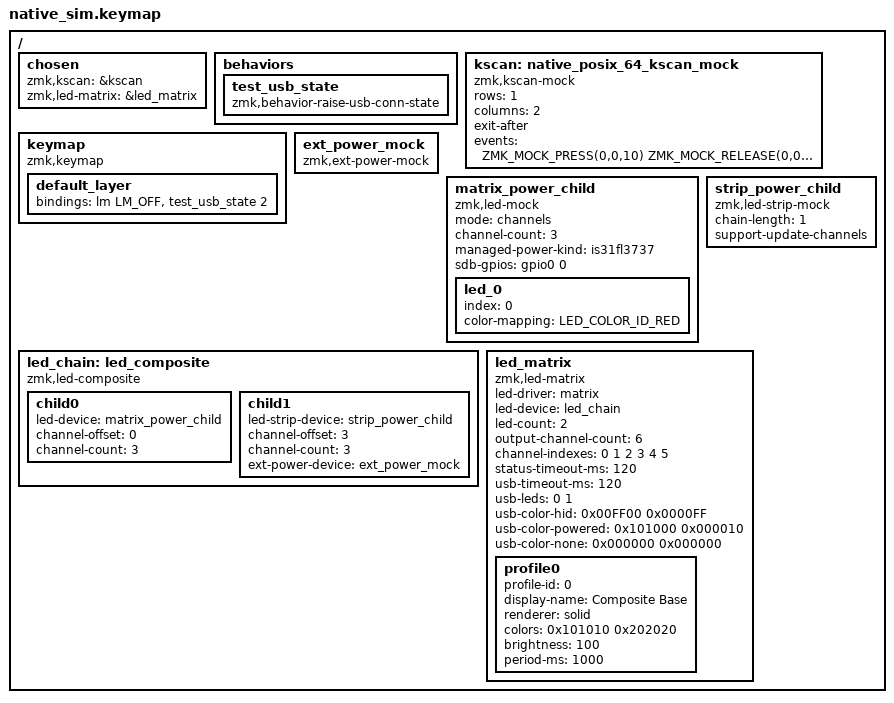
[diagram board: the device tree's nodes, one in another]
#include <dt-bindings/zmk/keys.h>
#include <dt-bindings/zmk/kscan_mock.h>
#include <dt-bindings/zmk/led_matrix.h>
#include <dt-bindings/led/led.h>
#include <behaviors.dtsi>

/ {
    chosen {
        zmk,kscan = &kscan;
        zmk,led-matrix = &led_matrix;
    };

    behaviors {
        test_usb_state: test_usb_state {
            compatible = "zmk,behavior-raise-usb-conn-state";
            #binding-cells = <1>;
        };
    };

    kscan: native_posix_64_kscan_mock {
        compatible = "zmk,kscan-mock";
        rows = <1>;
        columns = <2>;
        exit-after;
        events = <
            ZMK_MOCK_PRESS(0,0,10)
            ZMK_MOCK_RELEASE(0,0,10)
            ZMK_MOCK_PRESS(0,1,20)
            ZMK_MOCK_RELEASE(0,1,200)
        >;
    };

    keymap {
        compatible = "zmk,keymap";

        default_layer {
            bindings = <
                &lm LM_OFF
                &test_usb_state 2
            >;
        };
    };

    ext_power_mock: ext_power_mock {
        compatible = "zmk,ext-power-mock";
    };

    matrix_power_child: matrix_power_child {
        compatible = "zmk,led-mock";
        mode = "channels";
        channel-count = <3>;
        managed-power-kind = "is31fl3737";
        sdb-gpios = <&gpio0 0 GPIO_ACTIVE_HIGH>;

        led_0 {
            index = <0>;
            color-mapping = <LED_COLOR_ID_RED>;
        };
    };

    strip_power_child: strip_power_child {
        compatible = "zmk,led-strip-mock";
        chain-length = <1>;
        support-update-channels;
    };

    led_chain: led_composite {
        compatible = "zmk,led-composite";

        child0 {
            led-device = <&matrix_power_child>;
            channel-offset = <0>;
            channel-count = <3>;
        };

        child1 {
            led-strip-device = <&strip_power_child>;
            channel-offset = <3>;
            channel-count = <3>;
            ext-power-device = <&ext_power_mock>;
        };
    };

    led_matrix: led_matrix {
        compatible = "zmk,led-matrix";
        led-driver = "matrix";
        led-device = <&led_chain>;
        led-count = <2>;
        output-channel-count = <6>;
        channel-indexes = <
            0 1 2
            3 4 5
        >;
        status-timeout-ms = <120>;
        usb-timeout-ms = <120>;
        usb-leds = <0 1>;
        usb-color-hid = <0x00FF00 0x0000FF>;
        usb-color-powered = <0x101000 0x000010>;
        usb-color-none = <0x000000 0x000000>;

        profile0 {
            profile-id = <0>;
            display-name = "Composite Base";
            renderer = "solid";
            colors = <0x101010 0x202020>;
            brightness = <100>;
            period-ms = <1000>;
        };
    };
};
